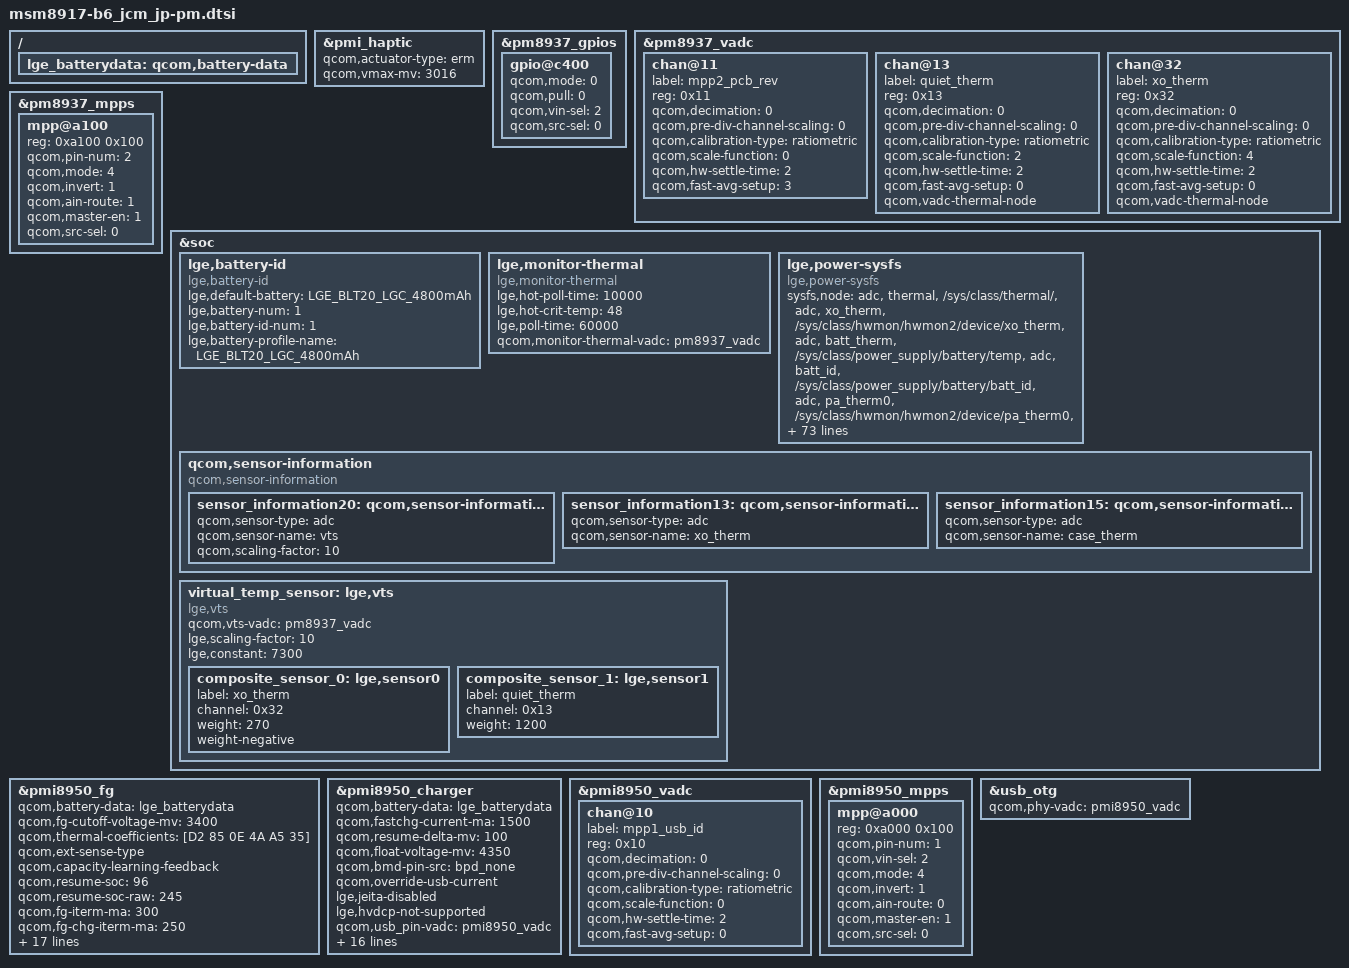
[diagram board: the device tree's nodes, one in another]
/*
 * Copyright (c) 2016, The Linux Foundation. All rights reserved.
 *
 * This program is free software; you can redistribute it and/or modify
 * it under the terms of the GNU General Public License version 2 and
 * only version 2 as published by the Free Software Foundation.
 *
 * This program is distributed in the hope that it will be useful,
 * but WITHOUT ANY WARRANTY; without even the implied warranty of
 * MERCHANTABILITY or FITNESS FOR A PARTICULAR PURPOSE.  See the
 * GNU General Public License for more details.
 */

&pmi_haptic{
	status = "okay";
	qcom,actuator-type = "erm";
	qcom,vmax-mv = <3016>;
};

/{
	lge_batterydata: qcom,battery-data {
		#include "../battery_profile/LGE_BLT20_LGC_4800mAh.dtsi"
	};
};

&pm8937_gpios {
	gpio@c400 {
		qcom,mode = <0>;
		qcom,pull = <0>;
		qcom,vin-sel = <2>;
		qcom,src-sel = <0>;
		status = "okay";
	};
};

&pm8937_vadc {
	chan@11 {
		label = "mpp2_pcb_rev";
		reg = <0x11>;
		qcom,decimation = <0>;
		qcom,pre-div-channel-scaling = <0>;
		qcom,calibration-type = "ratiometric";
		qcom,scale-function = <0>;
		qcom,hw-settle-time = <2>;
		qcom,fast-avg-setup = <3>;
	};

	chan@13 {
		label = "quiet_therm";
		reg = <0x13>;
		qcom,decimation = <0>;
		qcom,pre-div-channel-scaling = <0>;
		qcom,calibration-type = "ratiometric";
		qcom,scale-function = <2>;
		qcom,hw-settle-time = <2>;
		qcom,fast-avg-setup = <0>;
		qcom,vadc-thermal-node;
	};

	chan@32 {
		label = "xo_therm";
		reg = <0x32>;
		qcom,decimation = <0>;
		qcom,pre-div-channel-scaling = <0>;
		qcom,calibration-type = "ratiometric";
		qcom,scale-function = <4>;
		qcom,hw-settle-time = <2>;
		qcom,fast-avg-setup = <0>;
		qcom,vadc-thermal-node;
	};
};

&pm8937_mpps {
	mpp@a100 {
		reg = <0xa100 0x100>;
		qcom,pin-num = <2>;
		qcom,mode = <4>; /* AIN input */
		qcom,invert = <1>; /* Enable MPP */
		qcom,ain-route = <1>; /* AMUX 6 */
		qcom,master-en = <1>;
		qcom,src-sel = <0>; /* Function constant */
	};
};

&soc {
	lge,battery-id{
		compatible = "lge,battery-id";
		/delete-property/ lge,restrict-mode-enabled;
		lge,default-battery = "LGE_BLT20_LGC_4800mAh";
		/*Total number of combined of battery cell and battery id */
		lge,battery-num = <1>;
		/* battery id and battery profile match numbers */
		lge,battery-id-num = <1>;
		/* battery profile */
		lge,battery-profile-name = "LGE_BLT20_LGC_4800mAh";
	};

	lge,monitor-thermal {
		compatible = "lge,monitor-thermal";
		status = "ok";
		lge,hot-poll-time = <10000>;
		lge,hot-crit-temp = <48>;
		lge,poll-time = <60000>;
		qcom,monitor-thermal-vadc = <&pm8937_vadc>;
	};

	lge,power-sysfs {
		compatible = "lge,power-sysfs";

		sysfs,node =
			/* group , user_node,  kernel node */
			/* ADC/MPP */
			"adc", "thermal", "/sys/class/thermal/",
			"adc", "xo_therm", "/sys/class/hwmon/hwmon2/device/xo_therm",
			"adc", "batt_therm", "/sys/class/power_supply/battery/temp",
			"adc", "batt_id", "/sys/class/power_supply/battery/batt_id",
			"adc", "pa_therm0", "/sys/class/hwmon/hwmon2/device/pa_therm0",
			"adc", "pa_therm1", "NULL", /* Not use */
			"adc", "usb_in", "/sys/class/hwmon/hwmon7/device/usbin",
			"adc", "vcoin", "/sys/class/hwmon/hwmon2/device/vcoin",
			"adc", "vph_pwr", "/sys/class/hwmon/hwmon2/device/vph_pwr",
			"adc", "usb_id", "/sys/class/hwmon/hwmon7/device/mpp1_usb_id",
			"adc", "quiet_therm", "/sys/class/hwmon/hwmon2/device/quiet_therm",
			/* Battery */
			"battery", "capacity", "/sys/class/power_supply/battery/capacity",
			"battery", "health", "/sys/class/power_supply/battery/health",
			"battery", "present", "/sys/class/power_supply/battery/present",
			"battery", "pseudo_batt", "/sys/class/power_supply/battery/pseudo_batt",
			"battery", "status", "/sys/class/power_supply/battery/status",
			"battery", "temp", "/sys/class/power_supply/battery/temp",
			"battery", "valid_batt_id", "/sys/class/power_supply/battery/valid_batt_id",
			"battery", "voltage_now", "/sys/class/power_supply/battery/voltage_now",
			/* Charger */
			"charger", "ac_online", "NULL",
			"charger", "usb_online", "/sys/class/power_supply/usb/online",
			"charger", "present", "/sys/class/power_supply/usb/present",
			"charger", "wlc_online", "NULL",
			"charger", "type", "/sys/class/power_supply/usb/type",
			"charger", "time_out", "/sys/class/power_supply/battery/safety_timer_enabled",
			"charger", "charging_enabled", "/sys/class/power_supply/battery/charging_enabled",
			"charger", "ibat_current", "/sys/class/power_supply/battery/current_now",
			"charger", "ichg_current", "/sys/class/power_supply/usb/current_max",
			"charger", "iusb_control", "NULL",
			"charger", "thermal_mitigation", "/sys/module/qpnp_linear_charger/parameters/qpnp_thermal_mitigation", /* Fix */
			"charger", "wlc_thermal_mitigation", "NULL",
			"charger", "usb_parallel_chg_status", "NULL",
			"charger", "usb_parallel_charging_enabled", "NULL",
			"charger", "quick_charging_state", "/sys/module/qpnp_smbcharger/parameters/quick_charging_state",
			/* LCD Backlight */
			"lcd", "brightness", "/sys/class/leds/lcd-backlight/brightness",
			"lcd", "max_brightness", "/sys/class/leds/lcd-backlight/max_brightness",
			/* KEY LED */
			"key_led", "red_brightness", "NULL",
			"key_led", "green_brightness", "NULL",
			"key_led", "blue_brightness", "NULL",
			/* CPU */
			"cpu", "cpu_idle_modes", "NULL",
			/* GPU */
			"gpu", "busy", "/sys/class/kgsl/kgsl-3d0/gpubusy",
			/* PLATFORM */
			"platform", "speed_bin", "NULL",
			"platform", "pvs_bin", "NULL",
			"platform", "power_state", "/sys/power/autosleep",
			"platform", "poweron_alarm", "/sys/module/qpnp_rtc/parameters/poweron_alarm",
			"platform", "pcb_rev", "/sys/class/power_supply/battery/hw_rev",
			/* testmode */
			"testmode", "charge", "/sys/class/power_supply/battery/device/at_charge",
			"testmode", "chcomp", "/sys/class/power_supply/battery/device/at_chcomp",
			"testmode", "chgmodeoff", "/sys/class/power_supply/battery/charging_enabled",
			"testmode", "fuelrst", "NULL",
			"testmode", "rtc_time", "/dev/rtc0",
			"testmode", "pmrst", "NULL",
			"testmode", "battexit", "/sys/class/power_supply/battery/present"
			;
	};

	qcom,sensor-information {
		compatible = "qcom,sensor-information";

		sensor_information20: qcom,sensor-information-12 {
			qcom,sensor-type = "adc";
			qcom,sensor-name = "vts";
			qcom,scaling-factor = <10>;
		};

		sensor_information13: qcom,sensor-information-13 {
			qcom,sensor-type = "adc";
			qcom,sensor-name = "xo_therm";
		};

		sensor_information15: qcom,sensor-information-15 {
			qcom,sensor-type = "adc";
			qcom,sensor-name = "case_therm";
		};
	};

	/* vts = (-0.27*xo_therm) + (1.20*quiet_therm) + 7.3 */
	virtual_temp_sensor: lge,vts {
		compatible = "lge,vts";
		qcom,vts-vadc = <&pm8937_vadc>;
		lge,scaling-factor= <10>;
		lge,constant = <7300>;
		composite_sensor_0: lge,sensor0 {
			label = "xo_therm";
			channel = <0x32>;
			weight = <270>;
			weight-negative;
		};
		composite_sensor_1: lge,sensor1 {
			label = "quiet_therm";
			channel = <0x13>;
			weight = <1200>;
		};
	};
};

&pmi8950_fg {
	qcom,battery-data = <&lge_batterydata>;
	qcom,fg-cutoff-voltage-mv = <3400>;
	qcom,thermal-coefficients = [D2 85 0E 4A A5 35];
	qcom,ext-sense-type;
	qcom,capacity-learning-feedback;
	qcom,resume-soc = <96>;
	qcom,resume-soc-raw = <245>;
	qcom,fg-iterm-ma = <300>;
	qcom,fg-chg-iterm-ma = <250>;
	qcom,vbat-estimate-diff-mv = <250>;
	qcom,fg-cc-cv-threshold-mv = <4390>;
	qcom,esr-pulse-tuning-en;
	qcom,fg-use-vbat-low-empty-soc;
	qcom,fg-reset-on-lockup;
	qcom,fg-cc-soc-limit-pct = <120>;
	qcom,fg-control-slope-limiter;
	qcom,fg-slope-limit-high-temp-chg = <6>;
	qcom,fg-slope-limit-high-temp-dischg = <6>;
	qcom,fg-slope-limit-low-temp-chg = <14>;
	qcom,fg-slope-limit-low-temp-dischg =<14>;
	qcom,fg-dischg-voltage-gain-ctrl;
	qcom,fg-dischg-voltage-gain-soc = <7 15 20>;
	qcom,fg-dischg-med-voltage-gain = <5 4 4>;
	qcom,fg-dischg-high-voltage-gain = <5 5 4>;
	qcom,cl-max-limit-deciperc= <50>;
	qcom,cl-min-limit-deciperc= <200>;
};

&pmi8950_charger {
	qcom,battery-data = <&lge_batterydata>;
	qcom,fastchg-current-ma = <1500>;
	qcom,resume-delta-mv = <100>;
	qcom,float-voltage-mv = <4350>;
	qcom,bmd-pin-src = "bpd_none";
	qcom,override-usb-current;
	lge,jeita-disabled;
	lge,hvdcp-not-supported;

	qcom,usb_pin-vadc = <&pmi8950_vadc>;

	/* ref resistance 200K */
	lge,no-init-cable = <0 0 0>;
	lge,cable-mhl-1k = <5000 500 500>;
	lge,cable-u-28p7k = <10000 1800 500>;
	lge,cable-28p7k = <250000 1800 500>;
	lge,cable-56k = <600000 1500 1500>;
	lge,cable-100k = <620000 1800 500>;
	lge,cable-130k = <780000 1500 1500>;
	lge,cable-180k = <870000 1800 500>;
	lge,cable-200k = <910000 1800 500>;
	lge,cable-220k = <960000 1800 500>;
	lge,cable-270k = <1050000 1800 500>;
	lge,cable-330k = <1150000 1800 500>;
	lge,cable-620k = <1380000 1800 500>;
	lge,cable-910k = <1630000 1500 1500>;
	lge,cable-none = <1900000 1800  500>;

	lge,usb-max-current-ma = <1800>;
};

&pmi8950_vadc {
	chan@10 {
		label = "mpp1_usb_id";
		reg = <0x10>;
		qcom,decimation = <0>;
		qcom,pre-div-channel-scaling = <0>;
		qcom,calibration-type = "ratiometric";
		qcom,scale-function = <0>;
		qcom,hw-settle-time = <2>;
		qcom,fast-avg-setup = <0>;
	};
};

&pmi8950_mpps {
	mpp@a000 {
		reg = <0xa000 0x100>;
		qcom,pin-num = <1>;
		status = "okay";
		qcom,vin-sel = <2>;
		qcom,mode = <4>; /* AIN input */
		qcom,invert = <1>; /* Enable MPP */
		qcom,ain-route = <0>; /* AMUX 5 */
		qcom,master-en = <1>;
		qcom,src-sel = <0>; /* Function constant */
	};
};

&usb_otg {
	qcom,phy-vadc = <&pmi8950_vadc>;
};
